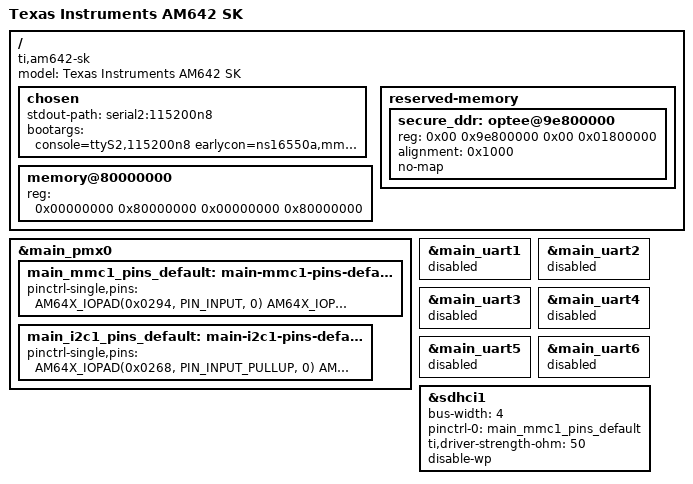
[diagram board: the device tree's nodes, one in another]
// SPDX-License-Identifier: GPL-2.0
/*
 * Copyright (C) 2021 Texas Instruments Incorporated - https://www.ti.com/
 */

/dts-v1/;

#include <dt-bindings/gpio/gpio.h>
#include "k3-am642.dtsi"

/ {
	compatible =  "ti,am642-sk", "ti,am642";
	model = "Texas Instruments AM642 SK";

	chosen {
		stdout-path = "serial2:115200n8";
		bootargs = "console=ttyS2,115200n8 earlycon=ns16550a,mmio32,0x02800000";
	};

	memory@80000000 {
		device_type = "memory";
		/* 2G RAM */
		reg = <0x00000000 0x80000000 0x00000000 0x80000000>;

	};

	reserved-memory {
		#address-cells = <2>;
		#size-cells = <2>;
		ranges;

		secure_ddr: optee@9e800000 {
			reg = <0x00 0x9e800000 0x00 0x01800000>; /* for OP-TEE */
			alignment = <0x1000>;
			no-map;
		};
	};
};

&main_pmx0 {
	main_mmc1_pins_default: main-mmc1-pins-default {
		pinctrl-single,pins = <
			AM64X_IOPAD(0x0294, PIN_INPUT, 0) /* (J19) MMC1_CMD */
			AM64X_IOPAD(0x0290, PIN_INPUT, 0) /* (#N/A) MMC1_CLKLB */
			AM64X_IOPAD(0x028c, PIN_INPUT, 0) /* (L20) MMC1_CLK */
			AM64X_IOPAD(0x0288, PIN_INPUT, 0) /* (K21) MMC1_DAT0 */
			AM64X_IOPAD(0x0284, PIN_INPUT, 0) /* (L21) MMC1_DAT1 */
			AM64X_IOPAD(0x0280, PIN_INPUT, 0) /* (K19) MMC1_DAT2 */
			AM64X_IOPAD(0x027c, PIN_INPUT, 0) /* (K18) MMC1_DAT3 */
			AM64X_IOPAD(0x0298, PIN_INPUT, 0) /* (D19) MMC1_SDCD */
		>;
	};

	main_i2c1_pins_default: main-i2c1-pins-default {
		pinctrl-single,pins = <
			AM64X_IOPAD(0x0268, PIN_INPUT_PULLUP, 0) /* (C18) I2C1_SCL */
			AM64X_IOPAD(0x026c, PIN_INPUT_PULLUP, 0) /* (B19) I2C1_SDA */
		>;
	};
};

&main_uart1 {
	/* main_uart1 is reserved for firmware usage */
	status = "reserved";
};

&main_uart2 {
	status = "disabled";
};

&main_uart3 {
	status = "disabled";
};

&main_uart4 {
	status = "disabled";
};

&main_uart5 {
	status = "disabled";
};

&main_uart6 {
	status = "disabled";
};

&sdhci1 {
	/* SD/MMC */
	pinctrl-names = "default";
	bus-width = <4>;
	pinctrl-0 = <&main_mmc1_pins_default>;
	ti,driver-strength-ohm = <50>;
	disable-wp;
};
